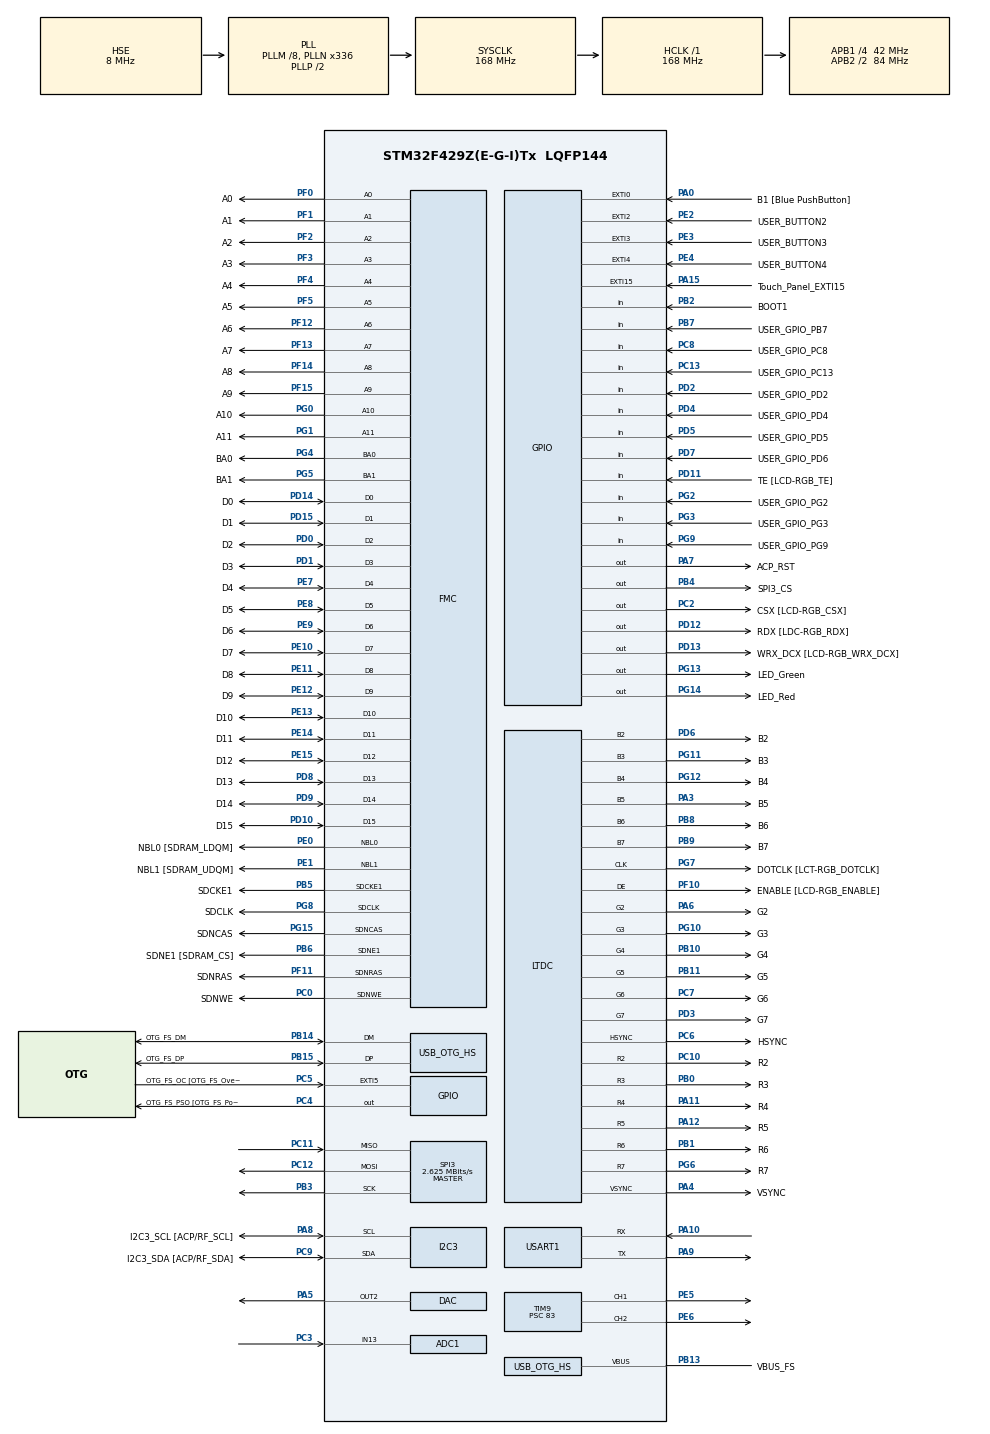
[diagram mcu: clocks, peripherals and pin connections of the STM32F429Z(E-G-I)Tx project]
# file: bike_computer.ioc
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ADC1.Channel-12\#ChannelRegularConversion=ADC_CHANNEL_13
ADC1.ClockPrescaler=ADC_CLOCK_SYNC_PCLK_DIV4
ADC1.ContinuousConvMode=ENABLE
ADC1.DMAContinuousRequests=ENABLE
ADC1.DataAlign=ADC_DATAALIGN_RIGHT
ADC1.DiscontinuousConvMode=DISABLE
ADC1.EOCSelection=ADC_EOC_SINGLE_CONV
ADC1.EnableAnalogWatchDog=false
ADC1.ExternalTrigConv=ADC_SOFTWARE_START
ADC1.ExternalTrigConvEdge=ADC_EXTERNALTRIGCONVEDGE_NONE
ADC1.InjNumberOfConversion=0
ADC1.NbrOfConversion=1
ADC1.NbrOfConversionFlag=1
ADC1.Rank-12\#ChannelRegularConversion=1
ADC1.Resolution=ADC_RESOLUTION_12B
ADC1.SamplingTime-12\#ChannelRegularConversion=ADC_SAMPLETIME_480CYCLES
ADC1.ScanConvMode=ENABLE
ADC1.master=1
Dma.ADC1.1.Direction=DMA_PERIPH_TO_MEMORY
Dma.ADC1.1.FIFOMode=DMA_FIFOMODE_DISABLE
Dma.ADC1.1.Instance=DMA2_Stream0
Dma.ADC1.1.MemDataAlignment=DMA_MDATAALIGN_WORD
Dma.ADC1.1.MemInc=DMA_MINC_ENABLE
Dma.ADC1.1.Mode=DMA_CIRCULAR
Dma.ADC1.1.PeriphDataAlignment=DMA_PDATAALIGN_WORD
Dma.ADC1.1.PeriphInc=DMA_PINC_DISABLE
Dma.ADC1.1.Priority=DMA_PRIORITY_LOW
Dma.Request0=USART1_RX
Dma.Request1=ADC1
Dma.USART1_RX.0.Direction=DMA_PERIPH_TO_MEMORY
Dma.USART1_RX.0.FIFOMode=DMA_FIFOMODE_DISABLE
Dma.USART1_RX.0.Instance=DMA2_Stream2
Dma.USART1_RX.0.MemDataAlignment=DMA_MDATAALIGN_BYTE
Dma.USART1_RX.0.MemInc=DMA_MINC_ENABLE
Dma.USART1_RX.0.Mode=DMA_CIRCULAR
Dma.USART1_RX.0.PeriphDataAlignment=DMA_PDATAALIGN_BYTE
Dma.USART1_RX.0.PeriphInc=DMA_PINC_DISABLE
Dma.USART1_RX.0.Priority=DMA_PRIORITY_LOW
FMC.CASLatency1=FMC_SDRAM_CAS_LATENCY_3
FMC.ExitSelfRefreshDelay1=7
FMC.LoadToActiveDelay1=2
FMC.RCDDelay1=2
FMC.RPDelay1=2
FMC.ReadPipeDelay1=FMC_SDRAM_RPIPE_DELAY_1
FMC.RowCycleDelay1=7
FMC.SDClockPeriod1=FMC_SDRAM_CLOCK_PERIOD_2
FMC.SelfRefreshTime1=4
FMC.WriteRecoveryTime1=3
FREERTOS.Tasks01=defaultTask,0,128,StartDefaultTask,Default,NULL
FREERTOS.configCHECK_FOR_STACK_OVERFLOW=1
FREERTOS.configTOTAL_HEAP_SIZE=30000
FREERTOS.configUSE_MALLOC_FAILED_HOOK=1
LTDC.ActiveH=320
LTDC.ActiveW=240
LTDC.Alpha_L0=255
LTDC.Alpha_L1=255
LTDC.BlendingFactor1_L0=LTDC_BLENDING_FACTOR1_PAxCA
LTDC.BlendingFactor1_L1=LTDC_BLENDING_FACTOR1_PAxCA
LTDC.BlendingFactor2_L0=LTDC_BLENDING_FACTOR2_PAxCA
LTDC.BlendingFactor2_L1=LTDC_BLENDING_FACTOR2_PAxCA
LTDC.HBP=20
LTDC.HFP=10
LTDC.HSync=10
LTDC.ImageHeight_L0=320
LTDC.ImageHeight_L1=320
LTDC.ImageWidth_L0=240
LTDC.ImageWidth_L1=240
LTDC.PCPolarity=LTDC_PCPOLARITY_IIPC
LTDC.PixelFormat_L0=LTDC_PIXEL_FORMAT_L8
LTDC.PixelFormat_L1=LTDC_PIXEL_FORMAT_L8
LTDC.VFP=4
LTDC.VSync=2
LTDC.WindowX1_L0=240
LTDC.WindowX1_L1=240
LTDC.WindowY1_L0=320
LTDC.WindowY1_L1=320
Mcu.Family=STM32F4
Mcu.Name=STM32F429Z(E-G-I)Tx
Mcu.Package=LQFP144
NVIC.DMA2_Stream0_IRQn=true\:5\:0\:false\:false\:true\:true\:false
NVIC.DMA2_Stream2_IRQn=true\:5\:0\:false\:false\:true\:true\:false
NVIC.EXTI15_10_IRQn=true\:5\:0\:false\:false\:true\:true\:true
NVIC.FMC_IRQn=true\:5\:0\:false\:false\:true\:true\:true
NVIC.LTDC_ER_IRQn=true\:5\:0\:false\:false\:true\:true\:true
NVIC.LTDC_IRQn=true\:5\:0\:false\:false\:true\:true\:true
NVIC.OTG_HS_EP1_IN_IRQn=true\:5\:0\:false\:false\:true\:true\:true
NVIC.OTG_HS_EP1_OUT_IRQn=true\:5\:0\:false\:false\:true\:true\:true
NVIC.OTG_HS_IRQn=true\:5\:0\:false\:false\:true\:true\:true
NVIC.PriorityGroup=NVIC_PRIORITYGROUP_4
NVIC.TIM1_UP_TIM10_IRQn=true\:0\:0\:false\:false\:true\:false\:false
NVIC.TimeBase=TIM1_UP_TIM10_IRQn
NVIC.TimeBaseIP=TIM1
NVIC.USART1_IRQn=true\:5\:0\:false\:false\:true\:true\:true
PA0/WKUP.GPIO_Label=B1 [Blue PushButton]
PA0/WKUP.GPIO_ModeDefaultEXTI=GPIO_MODE_EVT_RISING
PA0/WKUP.GPIO_PuPd=GPIO_NOPULL
PA0/WKUP.Signal=GPXTI0
PA10.Mode=Asynchronous
PA10.Signal=USART1_RX
PA11.GPIO_Label=R4
PA11.GPIO_Mode=GPIO_MODE_AF_PP
PA11.GPIO_PuPd=GPIO_NOPULL
PA11.GPIO_Speed=GPIO_SPEED_FREQ_LOW
PA11.Mode=RGB666
PA11.Signal=LTDC_R4
PA12.GPIO_Label=R5
PA12.GPIO_Mode=GPIO_MODE_AF_PP
PA12.GPIO_PuPd=GPIO_NOPULL
PA12.GPIO_Speed=GPIO_SPEED_FREQ_LOW
PA12.Mode=RGB666
PA12.Signal=LTDC_R5
PA13.GPIO_Label=SWDIO
PA13.Signal=SYS_JTMS-SWDIO
PA14.GPIO_Label=SWCLK
PA14.Signal=SYS_JTCK-SWCLK
PA15.GPIO_Label=Touch_Panel_EXTI15
PA15.Signal=GPXTI15
PA3.GPIO_Label=B5
PA3.GPIO_Mode=GPIO_MODE_AF_PP
PA3.GPIO_PuPd=GPIO_NOPULL
PA3.GPIO_Speed=GPIO_SPEED_FREQ_LOW
PA3.Mode=RGB666
PA3.Signal=LTDC_B5
PA4.GPIO_Label=VSYNC
PA4.GPIO_Mode=GPIO_MODE_AF_PP
PA4.GPIO_PuPd=GPIO_NOPULL
PA4.GPIO_Speed=GPIO_SPEED_FREQ_LOW
PA4.Mode=RGB666
PA4.Signal=LTDC_VSYNC
PA5.Signal=COMP_DAC2_group
PA6.GPIO_Label=G2
PA6.GPIO_Mode=GPIO_MODE_AF_PP
PA6.GPIO_PuPd=GPIO_NOPULL
PA6.GPIO_Speed=GPIO_SPEED_FREQ_LOW
PA6.Mode=RGB666
PA6.Signal=LTDC_G2
PA7.GPIO_Label=ACP_RST
PA7.GPIO_Mode=GPIO_MODE_OUTPUT_PP
PA7.GPIO_PuPd=GPIO_NOPULL
PA7.GPIO_Speed=GPIO_SPEED_FREQ_LOW
PA7.Signal=GPIO_Output
PA8.GPIO_Label=I2C3_SCL [ACP/RF_SCL]
PA8.GPIO_Mode=GPIO_MODE_AF_OD
PA8.GPIO_PuPd=GPIO_NOPULL
PA8.GPIO_Speed=GPIO_SPEED_FREQ_LOW
PA8.Mode=I2C
PA8.Signal=I2C3_SCL
PA9.Mode=Asynchronous
PA9.Signal=USART1_TX
PB0.GPIO_Label=R3
PB0.GPIO_Mode=GPIO_MODE_AF_PP
PB0.GPIO_PuPd=GPIO_NOPULL
PB0.GPIO_Speed=GPIO_SPEED_FREQ_LOW
PB0.Mode=RGB666
PB0.Signal=LTDC_R3
PB1.GPIO_Label=R6
PB1.GPIO_Mode=GPIO_MODE_AF_PP
PB1.GPIO_PuPd=GPIO_NOPULL
PB1.GPIO_Speed=GPIO_SPEED_FREQ_LOW
PB1.Mode=RGB666
PB1.Signal=LTDC_R6
PB10.GPIO_Label=G4
PB10.GPIO_Mode=GPIO_MODE_AF_PP
PB10.GPIO_PuPd=GPIO_NOPULL
PB10.GPIO_Speed=GPIO_SPEED_FREQ_LOW
PB10.Mode=RGB666
PB10.Signal=LTDC_G4
PB11.GPIO_Label=G5
PB11.GPIO_Mode=GPIO_MODE_AF_PP
PB11.GPIO_PuPd=GPIO_NOPULL
PB11.GPIO_Speed=GPIO_SPEED_FREQ_LOW
PB11.Mode=RGB666
PB11.Signal=LTDC_G5
PB12.GPIO_Label=OTG_FS_ID
PB12.GPIO_Mode=GPIO_MODE_AF_PP
PB12.GPIO_PuPd=GPIO_NOPULL
PB12.GPIO_Speed=GPIO_SPEED_FREQ_LOW
PB12.Signal=USB_OTG_HS_ID
PB13.GPIO_Label=VBUS_FS
PB13.GPIO_Mode=GPIO_MODE_INPUT
PB13.GPIO_PuPd=GPIO_NOPULL
PB13.Mode=Activate_VBUS_FS
PB13.Signal=USB_OTG_HS_VBUS
PB14.GPIO_Label=OTG_FS_DM
PB14.GPIO_Mode=GPIO_MODE_AF_PP
PB14.GPIO_PuPd=GPIO_NOPULL
PB14.GPIO_Speed=GPIO_SPEED_FREQ_LOW
PB14.Mode=Device_Only_FS
PB14.Signal=USB_OTG_HS_DM
PB15.GPIO_Label=OTG_FS_DP
PB15.GPIO_Mode=GPIO_MODE_AF_PP
PB15.GPIO_PuPd=GPIO_NOPULL
PB15.GPIO_Speed=GPIO_SPEED_FREQ_LOW
PB15.Mode=Device_Only_FS
PB15.Signal=USB_OTG_HS_DP
PB2/BOOT1.GPIO_Label=BOOT1
PB2/BOOT1.GPIO_Mode=GPIO_MODE_INPUT
PB2/BOOT1.GPIO_PuPd=GPIO_NOPULL
PB2/BOOT1.Signal=GPIO_Input
PB3.Mode=Full_Duplex_Master
PB3.Signal=SPI3_SCK
PB4.GPIO_Label=SPI3_CS
PB4.Signal=GPIO_Output
PB5.GPIO_Label=SDCKE1
PB5.GPIO_Mode=GPIO_MODE_AF_PP
PB5.GPIO_PuPd=GPIO_NOPULL
PB5.GPIO_Speed=GPIO_SPEED_FREQ_VERY_HIGH
PB5.Mode=SdramChipSelect2_1
PB5.Signal=FMC_SDCKE1
PB6.GPIO_Label=SDNE1 [SDRAM_CS]
PB6.GPIO_Mode=GPIO_MODE_AF_PP
PB6.GPIO_PuPd=GPIO_NOPULL
PB6.GPIO_Speed=GPIO_SPEED_FREQ_VERY_HIGH
PB6.Mode=SdramChipSelect2_1
PB6.Signal=FMC_SDNE1
PB7.GPIO_Label=USER_GPIO_PB7
PB7.Signal=GPIO_Input
PB8.GPIO_Label=B6
PB8.GPIO_Mode=GPIO_MODE_AF_PP
PB8.GPIO_PuPd=GPIO_NOPULL
PB8.GPIO_Speed=GPIO_SPEED_FREQ_LOW
PB8.Mode=RGB666
PB8.Signal=LTDC_B6
PB9.GPIO_Label=B7
PB9.GPIO_Mode=GPIO_MODE_AF_PP
PB9.GPIO_PuPd=GPIO_NOPULL
PB9.GPIO_Speed=GPIO_SPEED_FREQ_LOW
PB9.Mode=RGB666
PB9.Signal=LTDC_B7
PC0.GPIO_Label=SDNWE
PC0.GPIO_Mode=GPIO_MODE_AF_PP
PC0.GPIO_PuPd=GPIO_NOPULL
PC0.GPIO_Speed=GPIO_SPEED_FREQ_VERY_HIGH
PC0.Signal=FMC_SDNWE
PC10.GPIO_Label=R2
PC10.GPIO_Mode=GPIO_MODE_AF_PP
PC10.GPIO_PuPd=GPIO_NOPULL
PC10.GPIO_Speed=GPIO_SPEED_FREQ_LOW
PC10.Mode=RGB666
PC10.Signal=LTDC_R2
PC11.Mode=Full_Duplex_Master
PC11.Signal=SPI3_MISO
PC12.Mode=Full_Duplex_Master
PC12.Signal=SPI3_MOSI
PC13.GPIO_Label=USER_GPIO_PC13
PC13.Signal=GPIO_Input
PC14/OSC32_IN.GPIO_Label=PC14-OSC32_IN
PC14/OSC32_IN.Signal=RCC_OSC32_IN
PC15/OSC32_OUT.GPIO_Label=PC15-OSC32_OUT
PC15/OSC32_OUT.Signal=RCC_OSC32_OUT
PC2.GPIO_Label=CSX [LCD-RGB_CSX]
PC2.GPIO_Mode=GPIO_MODE_OUTPUT_PP
PC2.GPIO_PuPd=GPIO_NOPULL
PC2.GPIO_Speed=GPIO_SPEED_FREQ_LOW
PC2.Signal=GPIO_Output
PC3.Signal=ADCx_IN13
PC4.GPIO_Label=OTG_FS_PSO [OTG_FS_PowerSwitchOn]
PC4.GPIO_Mode=GPIO_MODE_OUTPUT_PP
PC4.GPIO_PuPd=GPIO_NOPULL
PC4.GPIO_Speed=GPIO_SPEED_FREQ_LOW
PC4.Signal=GPIO_Output
PC5.GPIO_Label=OTG_FS_OC [OTG_FS_OverCurrent]
PC5.GPIO_ModeDefaultEXTI=GPIO_MODE_EVT_RISING
PC5.Signal=GPXTI5
PC6.GPIO_Label=HSYNC
PC6.GPIO_Mode=GPIO_MODE_AF_PP
PC6.GPIO_PuPd=GPIO_NOPULL
PC6.GPIO_Speed=GPIO_SPEED_FREQ_LOW
PC6.Mode=RGB666
PC6.Signal=LTDC_HSYNC
PC7.GPIO_Label=G6
PC7.GPIO_Mode=GPIO_MODE_AF_PP
PC7.GPIO_PuPd=GPIO_NOPULL
PC7.GPIO_Speed=GPIO_SPEED_FREQ_LOW
PC7.Mode=RGB666
PC7.Signal=LTDC_G6
PC8.GPIO_Label=USER_GPIO_PC8
PC8.Signal=GPIO_Input
PC9.GPIO_Label=I2C3_SDA [ACP/RF_SDA]
PC9.GPIO_Mode=GPIO_MODE_AF_OD
PC9.GPIO_PuPd=GPIO_NOPULL
PC9.GPIO_Speed=GPIO_SPEED_FREQ_LOW
PC9.Mode=I2C
PC9.Signal=I2C3_SDA
PD0.GPIO_Label=D2
PD0.GPIO_Mode=GPIO_MODE_AF_PP
PD0.GPIO_PuPd=GPIO_NOPULL
PD0.GPIO_Speed=GPIO_SPEED_FREQ_VERY_HIGH
PD0.Signal=FMC_D2_DA2
PD1.GPIO_Label=D3
PD1.GPIO_Mode=GPIO_MODE_AF_PP
PD1.GPIO_PuPd=GPIO_NOPULL
PD1.GPIO_Speed=GPIO_SPEED_FREQ_VERY_HIGH
PD1.Signal=FMC_D3_DA3
PD10.GPIO_Label=D15
PD10.GPIO_Mode=GPIO_MODE_AF_PP
PD10.GPIO_PuPd=GPIO_NOPULL
PD10.GPIO_Speed=GPIO_SPEED_FREQ_VERY_HIGH
PD10.Signal=FMC_D15_DA15
PD11.GPIO_Label=TE [LCD-RGB_TE]
PD11.GPIO_Mode=GPIO_MODE_INPUT
PD11.GPIO_PuPd=GPIO_NOPULL
PD11.Signal=GPIO_Input
PD12.GPIO_Label=RDX [LDC-RGB_RDX]
PD12.GPIO_Mode=GPIO_MODE_OUTPUT_PP
PD12.GPIO_PuPd=GPIO_NOPULL
PD12.GPIO_Speed=GPIO_SPEED_FREQ_LOW
PD12.Signal=GPIO_Output
PD13.GPIO_Label=WRX_DCX [LCD-RGB_WRX_DCX]
PD13.GPIO_Mode=GPIO_MODE_OUTPUT_PP
PD13.GPIO_PuPd=GPIO_NOPULL
PD13.GPIO_Speed=GPIO_SPEED_FREQ_LOW
PD13.Signal=GPIO_Output
PD14.GPIO_Label=D0
PD14.GPIO_Mode=GPIO_MODE_AF_PP
PD14.GPIO_PuPd=GPIO_NOPULL
PD14.GPIO_Speed=GPIO_SPEED_FREQ_VERY_HIGH
PD14.Signal=FMC_D0_DA0
PD15.GPIO_Label=D1
PD15.GPIO_Mode=GPIO_MODE_AF_PP
PD15.GPIO_PuPd=GPIO_NOPULL
PD15.GPIO_Speed=GPIO_SPEED_FREQ_VERY_HIGH
PD15.Signal=FMC_D1_DA1
PD2.GPIO_Label=USER_GPIO_PD2
PD2.Signal=GPIO_Input
PD3.GPIO_Label=G7
PD3.GPIO_Mode=GPIO_MODE_AF_PP
PD3.GPIO_PuPd=GPIO_NOPULL
PD3.GPIO_Speed=GPIO_SPEED_FREQ_LOW
PD3.Mode=RGB666
PD3.Signal=LTDC_G7
PD4.GPIO_Label=USER_GPIO_PD4
PD4.Signal=GPIO_Input
PD5.GPIO_Label=USER_GPIO_PD5
PD5.Signal=GPIO_Input
PD6.GPIO_Label=B2
PD6.GPIO_Mode=GPIO_MODE_AF_PP
PD6.GPIO_PuPd=GPIO_NOPULL
PD6.GPIO_Speed=GPIO_SPEED_FREQ_LOW
PD6.Mode=RGB666
PD6.Signal=LTDC_B2
PD7.GPIO_Label=USER_GPIO_PD6
PD7.Signal=GPIO_Input
PD8.GPIO_Label=D13
PD8.GPIO_Mode=GPIO_MODE_AF_PP
PD8.GPIO_PuPd=GPIO_NOPULL
PD8.GPIO_Speed=GPIO_SPEED_FREQ_VERY_HIGH
PD8.Signal=FMC_D13_DA13
PD9.GPIO_Label=D14
PD9.GPIO_Mode=GPIO_MODE_AF_PP
PD9.GPIO_PuPd=GPIO_NOPULL
PD9.GPIO_Speed=GPIO_SPEED_FREQ_VERY_HIGH
PD9.Signal=FMC_D14_DA14
PE0.GPIO_Label=NBL0 [SDRAM_LDQM]
PE0.GPIO_Mode=GPIO_MODE_AF_PP
PE0.GPIO_PuPd=GPIO_NOPULL
PE0.GPIO_Speed=GPIO_SPEED_FREQ_VERY_HIGH
PE0.Signal=FMC_NBL0
PE1.GPIO_Label=NBL1 [SDRAM_UDQM]
PE1.GPIO_Mode=GPIO_MODE_AF_PP
PE1.GPIO_PuPd=GPIO_NOPULL
PE1.GPIO_Speed=GPIO_SPEED_FREQ_VERY_HIGH
PE1.Signal=FMC_NBL1
PE10.GPIO_Label=D7
PE10.GPIO_Mode=GPIO_MODE_AF_PP
PE10.GPIO_PuPd=GPIO_NOPULL
PE10.GPIO_Speed=GPIO_SPEED_FREQ_VERY_HIGH
PE10.Signal=FMC_D7_DA7
PE11.GPIO_Label=D8
PE11.GPIO_Mode=GPIO_MODE_AF_PP
PE11.GPIO_PuPd=GPIO_NOPULL
PE11.GPIO_Speed=GPIO_SPEED_FREQ_VERY_HIGH
PE11.Signal=FMC_D8_DA8
PE12.GPIO_Label=D9
PE12.GPIO_Mode=GPIO_MODE_AF_PP
PE12.GPIO_PuPd=GPIO_NOPULL
PE12.GPIO_Speed=GPIO_SPEED_FREQ_VERY_HIGH
PE12.Signal=FMC_D9_DA9
PE13.GPIO_Label=D10
PE13.GPIO_Mode=GPIO_MODE_AF_PP
PE13.GPIO_PuPd=GPIO_NOPULL
PE13.GPIO_Speed=GPIO_SPEED_FREQ_VERY_HIGH
PE13.Signal=FMC_D10_DA10
PE14.GPIO_Label=D11
PE14.GPIO_Mode=GPIO_MODE_AF_PP
PE14.GPIO_PuPd=GPIO_NOPULL
PE14.GPIO_Speed=GPIO_SPEED_FREQ_VERY_HIGH
PE14.Signal=FMC_D11_DA11
PE15.GPIO_Label=D12
PE15.GPIO_Mode=GPIO_MODE_AF_PP
PE15.GPIO_PuPd=GPIO_NOPULL
PE15.GPIO_Speed=GPIO_SPEED_FREQ_VERY_HIGH
PE15.Signal=FMC_D12_DA12
PE2.GPIO_Label=USER_BUTTON2
PE2.Signal=GPXTI2
PE3.GPIO_Label=USER_BUTTON3
PE3.Signal=GPXTI3
PE4.GPIO_Label=USER_BUTTON4
PE4.Signal=GPXTI4
PE5.Signal=S_TIM9_CH1
PE6.Signal=S_TIM9_CH2
PE7.GPIO_Label=D4
PE7.GPIO_Mode=GPIO_MODE_AF_PP
PE7.GPIO_PuPd=GPIO_NOPULL
PE7.GPIO_Speed=GPIO_SPEED_FREQ_VERY_HIGH
PE7.Signal=FMC_D4_DA4
PE8.GPIO_Label=D5
PE8.GPIO_Mode=GPIO_MODE_AF_PP
PE8.GPIO_PuPd=GPIO_NOPULL
PE8.GPIO_Speed=GPIO_SPEED_FREQ_VERY_HIGH
PE8.Signal=FMC_D5_DA5
PE9.GPIO_Label=D6
PE9.GPIO_Mode=GPIO_MODE_AF_PP
PE9.GPIO_PuPd=GPIO_NOPULL
PE9.GPIO_Speed=GPIO_SPEED_FREQ_VERY_HIGH
PE9.Signal=FMC_D6_DA6
PF0.GPIO_Label=A0
PF0.GPIO_Mode=GPIO_MODE_AF_PP
PF0.GPIO_PuPd=GPIO_NOPULL
PF0.GPIO_Speed=GPIO_SPEED_FREQ_VERY_HIGH
PF0.Signal=FMC_A0
PF1.GPIO_Label=A1
PF1.GPIO_Mode=GPIO_MODE_AF_PP
PF1.GPIO_PuPd=GPIO_NOPULL
PF1.GPIO_Speed=GPIO_SPEED_FREQ_VERY_HIGH
PF1.Signal=FMC_A1
PF10.GPIO_Label=ENABLE [LCD-RGB_ENABLE]
PF10.GPIO_Mode=GPIO_MODE_AF_PP
PF10.GPIO_PuPd=GPIO_NOPULL
PF10.GPIO_Speed=GPIO_SPEED_FREQ_LOW
PF10.Mode=RGB666
PF10.Signal=LTDC_DE
PF11.GPIO_Label=SDNRAS
PF11.GPIO_Mode=GPIO_MODE_AF_PP
PF11.GPIO_PuPd=GPIO_NOPULL
PF11.GPIO_Speed=GPIO_SPEED_FREQ_VERY_HIGH
PF11.Signal=FMC_SDNRAS
PF12.GPIO_Label=A6
PF12.GPIO_Mode=GPIO_MODE_AF_PP
PF12.GPIO_PuPd=GPIO_NOPULL
PF12.GPIO_Speed=GPIO_SPEED_FREQ_VERY_HIGH
PF12.Signal=FMC_A6
PF13.GPIO_Label=A7
PF13.GPIO_Mode=GPIO_MODE_AF_PP
PF13.GPIO_PuPd=GPIO_NOPULL
PF13.GPIO_Speed=GPIO_SPEED_FREQ_VERY_HIGH
PF13.Signal=FMC_A7
PF14.GPIO_Label=A8
PF14.GPIO_Mode=GPIO_MODE_AF_PP
PF14.GPIO_PuPd=GPIO_NOPULL
PF14.GPIO_Speed=GPIO_SPEED_FREQ_VERY_HIGH
PF14.Signal=FMC_A8
PF15.GPIO_Label=A9
PF15.GPIO_Mode=GPIO_MODE_AF_PP
PF15.GPIO_PuPd=GPIO_NOPULL
PF15.GPIO_Speed=GPIO_SPEED_FREQ_VERY_HIGH
PF15.Signal=FMC_A9
PF2.GPIO_Label=A2
PF2.GPIO_Mode=GPIO_MODE_AF_PP
PF2.GPIO_PuPd=GPIO_NOPULL
PF2.GPIO_Speed=GPIO_SPEED_FREQ_VERY_HIGH
PF2.Signal=FMC_A2
PF3.GPIO_Label=A3
PF3.GPIO_Mode=GPIO_MODE_AF_PP
PF3.GPIO_PuPd=GPIO_NOPULL
PF3.GPIO_Speed=GPIO_SPEED_FREQ_VERY_HIGH
PF3.Signal=FMC_A3
PF4.GPIO_Label=A4
PF4.GPIO_Mode=GPIO_MODE_AF_PP
PF4.GPIO_PuPd=GPIO_NOPULL
PF4.GPIO_Speed=GPIO_SPEED_FREQ_VERY_HIGH
PF4.Signal=FMC_A4
PF5.GPIO_Label=A5
PF5.GPIO_Mode=GPIO_MODE_AF_PP
PF5.GPIO_PuPd=GPIO_NOPULL
PF5.GPIO_Speed=GPIO_SPEED_FREQ_VERY_HIGH
PF5.Signal=FMC_A5
PG0.GPIO_Label=A10
PG0.GPIO_Mode=GPIO_MODE_AF_PP
PG0.GPIO_PuPd=GPIO_NOPULL
PG0.GPIO_Speed=GPIO_SPEED_FREQ_VERY_HIGH
PG0.Signal=FMC_A10
PG1.GPIO_Label=A11
PG1.GPIO_Mode=GPIO_MODE_AF_PP
PG1.GPIO_PuPd=GPIO_NOPULL
PG1.GPIO_Speed=GPIO_SPEED_FREQ_VERY_HIGH
PG1.Signal=FMC_A11
PG10.GPIO_Label=G3
PG10.GPIO_Mode=GPIO_MODE_AF_PP
PG10.GPIO_PuPd=GPIO_NOPULL
PG10.GPIO_Speed=GPIO_SPEED_FREQ_LOW
PG10.Mode=RGB666
PG10.Signal=LTDC_G3
PG11.GPIO_Label=B3
PG11.GPIO_Mode=GPIO_MODE_AF_PP
PG11.GPIO_PuPd=GPIO_NOPULL
PG11.GPIO_Speed=GPIO_SPEED_FREQ_LOW
PG11.Mode=RGB666
PG11.Signal=LTDC_B3
PG12.GPIO_Label=B4
PG12.GPIO_Mode=GPIO_MODE_AF_PP
PG12.GPIO_PuPd=GPIO_NOPULL
PG12.GPIO_Speed=GPIO_SPEED_FREQ_LOW
PG12.Mode=RGB666
PG12.Signal=LTDC_B4
PG13.GPIO_Label=LED_Green
PG13.GPIO_Mode=GPIO_MODE_OUTPUT_PP
PG13.GPIO_PuPd=GPIO_NOPULL
PG13.GPIO_Speed=GPIO_SPEED_FREQ_LOW
PG13.Signal=GPIO_Output
PG14.GPIO_Label=LED_Red
PG14.GPIO_Mode=GPIO_MODE_OUTPUT_PP
PG14.GPIO_PuPd=GPIO_NOPULL
PG14.GPIO_Speed=GPIO_SPEED_FREQ_LOW
PG14.Signal=GPIO_Output
PG15.GPIO_Label=SDNCAS
PG15.GPIO_Mode=GPIO_MODE_AF_PP
PG15.GPIO_PuPd=GPIO_NOPULL
PG15.GPIO_Speed=GPIO_SPEED_FREQ_VERY_HIGH
PG15.Signal=FMC_SDNCAS
PG2.GPIO_Label=USER_GPIO_PG2
PG2.Signal=GPIO_Input
PG3.GPIO_Label=USER_GPIO_PG3
PG3.Signal=GPIO_Input
PG4.GPIO_Label=BA0
PG4.GPIO_Mode=GPIO_MODE_AF_PP
PG4.GPIO_PuPd=GPIO_NOPULL
PG4.GPIO_Speed=GPIO_SPEED_FREQ_VERY_HIGH
PG4.Signal=FMC_A14_BA0
PG5.GPIO_Label=BA1
PG5.GPIO_Mode=GPIO_MODE_AF_PP
PG5.GPIO_PuPd=GPIO_NOPULL
PG5.GPIO_Speed=GPIO_SPEED_FREQ_VERY_HIGH
PG5.Signal=FMC_A15_BA1
PG6.GPIO_Label=R7
PG6.GPIO_Mode=GPIO_MODE_AF_PP
PG6.GPIO_PuPd=GPIO_NOPULL
PG6.GPIO_Speed=GPIO_SPEED_FREQ_LOW
PG6.Mode=RGB666
PG6.Signal=LTDC_R7
PG7.GPIO_Label=DOTCLK [LCT-RGB_DOTCLK]
PG7.GPIO_Mode=GPIO_MODE_AF_PP
PG7.GPIO_PuPd=GPIO_NOPULL
PG7.GPIO_Speed=GPIO_SPEED_FREQ_LOW
PG7.Mode=RGB666
PG7.Signal=LTDC_CLK
PG8.GPIO_Label=SDCLK
PG8.GPIO_Mode=GPIO_MODE_AF_PP
PG8.GPIO_PuPd=GPIO_NOPULL
PG8.GPIO_Speed=GPIO_SPEED_FREQ_VERY_HIGH
PG8.Signal=FMC_SDCLK
PG9.GPIO_Label=USER_GPIO_PG9
PG9.Signal=GPIO_Input
PH0/OSC_IN.GPIO_Label=PH0-OSC_IN
PH0/OSC_IN.Mode=HSE-External-Oscillator
PH0/OSC_IN.Signal=RCC_OSC_IN
PH1/OSC_OUT.GPIO_Label=PH1-OSC_OUT
PH1/OSC_OUT.Mode=HSE-External-Oscillator
PH1/OSC_OUT.Signal=RCC_OSC_OUT
ProjectManager.HeapSize=0x200
ProjectManager.StackSize=0x400
ProjectManager.TargetToolchain=TrueSTUDIO
RCC.48MHZClocksFreq_Value=48000000
RCC.AHBFreq_Value=168000000
RCC.APB1CLKDivider=RCC_HCLK_DIV4
RCC.APB1Freq_Value=42000000
RCC.APB1TimFreq_Value=84000000
RCC.APB2CLKDivider=RCC_HCLK_DIV2
RCC.APB2Freq_Value=84000000
RCC.APB2TimFreq_Value=168000000
RCC.CortexFreq_Value=168000000
RCC.HCLKFreq_Value=168000000
RCC.HSE_VALUE=8000000
RCC.HSI_VALUE=16000000
RCC.LSE_VALUE=32768
RCC.PLLM=8
RCC.PLLN=336
RCC.PLLQ=7
RCC.PLLSAIDivR=RCC_PLLSAIDIVR_8
RCC.PLLSAIN=192
RCC.PLLSAIR=4
RCC.SYSCLKFreq_VALUE=168000000
RCC.SYSCLKSource=RCC_SYSCLKSOURCE_PLLCLK
RCC.VCOOutputFreq_Value=336000000
SH.ADCx_IN13.0=ADC1_IN13,IN13
SH.COMP_DAC2_group.0=DAC_OUT2,DAC_OUT2
SH.FMC_A0.0=FMC_A0,12b-sda1
SH.FMC_A1.0=FMC_A1,12b-sda1
SH.FMC_A10.0=FMC_A10,12b-sda1
SH.FMC_A11.0=FMC_A11,12b-sda1
SH.FMC_A14_BA0.0=FMC_BA0,FourSdramBanks1
SH.FMC_A15_BA1.0=FMC_BA1,FourSdramBanks1
SH.FMC_A2.0=FMC_A2,12b-sda1
SH.FMC_A3.0=FMC_A3,12b-sda1
SH.FMC_A4.0=FMC_A4,12b-sda1
SH.FMC_A5.0=FMC_A5,12b-sda1
SH.FMC_A6.0=FMC_A6,12b-sda1
SH.FMC_A7.0=FMC_A7,12b-sda1
SH.FMC_A8.0=FMC_A8,12b-sda1
SH.FMC_A9.0=FMC_A9,12b-sda1
SH.FMC_D0_DA0.0=FMC_D0,sd-16b-d1
SH.FMC_D10_DA10.0=FMC_D10,sd-16b-d1
SH.FMC_D11_DA11.0=FMC_D11,sd-16b-d1
SH.FMC_D12_DA12.0=FMC_D12,sd-16b-d1
SH.FMC_D13_DA13.0=FMC_D13,sd-16b-d1
SH.FMC_D14_DA14.0=FMC_D14,sd-16b-d1
SH.FMC_D15_DA15.0=FMC_D15,sd-16b-d1
SH.FMC_D1_DA1.0=FMC_D1,sd-16b-d1
SH.FMC_D2_DA2.0=FMC_D2,sd-16b-d1
SH.FMC_D3_DA3.0=FMC_D3,sd-16b-d1
SH.FMC_D4_DA4.0=FMC_D4,sd-16b-d1
SH.FMC_D5_DA5.0=FMC_D5,sd-16b-d1
SH.FMC_D6_DA6.0=FMC_D6,sd-16b-d1
SH.FMC_D7_DA7.0=FMC_D7,sd-16b-d1
SH.FMC_D8_DA8.0=FMC_D8,sd-16b-d1
SH.FMC_D9_DA9.0=FMC_D9,sd-16b-d1
SH.FMC_NBL0.0=FMC_NBL0,Sd2ByteEnable1
SH.FMC_NBL1.0=FMC_NBL1,Sd2ByteEnable1
SH.FMC_SDCLK.0=FMC_SDCLK,12b-sda1
SH.FMC_SDNCAS.0=FMC_SDNCAS,12b-sda1
SH.FMC_SDNRAS.0=FMC_SDNRAS,12b-sda1
SH.FMC_SDNWE.0=FMC_SDNWE,12b-sda1
SH.S_TIM9_CH1.0=TIM9_CH1,PWM Generation1 CH1
SH.S_TIM9_CH2.0=TIM9_CH2,PWM Generation2 CH2
SPI3.BaudRatePrescaler=SPI_BAUDRATEPRESCALER_16
SPI3.CalculateBaudRate=2.625 MBits/s
SPI3.Direction=SPI_DIRECTION_2LINES
SPI3.Mode=SPI_MODE_MASTER
SPI3.VirtualType=VM_MASTER
TIM9.Channel-PWM\ Generation1\ CH1=TIM_CHANNEL_1
TIM9.Channel-PWM\ Generation2\ CH2=TIM_CHANNEL_2
TIM9.Period=4999
TIM9.Prescaler=83
USART1.VirtualMode=VM_ASYNC
USB_DEVICE.CLASS_NAME_HS=CDC
USB_DEVICE.VirtualMode-CDC_HS=Cdc
USB_DEVICE.VirtualModeHS=Cdc_HS
USB_OTG_HS.VirtualMode-Device_Only_FS=Device_Only_FS
USB_OTG_HS.vbus_sensing_enable-Device_Only_FS=ENABLE
VP_FREERTOS_VS_ENABLE.Mode=Enabled
VP_SYS_VS_tim1.Mode=TIM1
VP_USB_DEVICE_VS_USB_DEVICE_CDC_HS.Mode=CDC_HS
board=STM32F429I-DISCO

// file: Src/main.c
/**
  ******************************************************************************
  * File Name          : main.c
  * Description        : Main program body
  ******************************************************************************
  * This notice applies to any and all portions of this file
  * that are not between comment pairs USER CODE BEGIN and
  * USER CODE END. Other portions of this file, whether
  * inserted by the user or by software development tools
  * are owned by their respective copyright owners.
  *
  * Copyright (c) 2017 STMicroelectronics International N.V.
  * All rights reserved.
  *
  * Redistribution and use in source and binary forms, with or without
  * modification, are permitted, provided that the following conditions are met:
  *
  * 1. Redistribution of source code must retain the above copyright notice,
  *    this list of conditions and the following disclaimer.
  * 2. Redistributions in binary form must reproduce the above copyright notice,
  *    this list of conditions and the following disclaimer in the documentation
  *    and/or other materials provided with the distribution.
  * 3. Neither the name of STMicroelectronics nor the names of other
  *    contributors to this software may be used to endorse or promote products
  *    derived from this software without specific written permission.
  * 4. This software, including modifications and/or derivative works of this
  *    software, must execute solely and exclusively on microcontroller or
  *    microprocessor devices manufactured by or for STMicroelectronics.
  * 5. Redistribution and use of this software other than as permitted under
  *    this license is void and will automatically terminate your rights under
  *    this license.
  *
  * THIS SOFTWARE IS PROVIDED BY STMICROELECTRONICS AND CONTRIBUTORS "AS IS"
  * AND ANY EXPRESS, IMPLIED OR STATUTORY WARRANTIES, INCLUDING, BUT NOT
  * LIMITED TO, THE IMPLIED WARRANTIES OF MERCHANTABILITY, FITNESS FOR A
  * PARTICULAR PURPOSE AND NON-INFRINGEMENT OF THIRD PARTY INTELLECTUAL PROPERTY
  * RIGHTS ARE DISCLAIMED TO THE FULLEST EXTENT PERMITTED BY LAW. IN NO EVENT
  * SHALL STMICROELECTRONICS OR CONTRIBUTORS BE LIABLE FOR ANY DIRECT, INDIRECT,
  * INCIDENTAL, SPECIAL, EXEMPLARY, OR CONSEQUENTIAL DAMAGES (INCLUDING, BUT NOT
  * LIMITED TO, PROCUREMENT OF SUBSTITUTE GOODS OR SERVICES; LOSS OF USE, DATA,
  * OR PROFITS; OR BUSINESS INTERRUPTION) HOWEVER CAUSED AND ON ANY THEORY OF
  * LIABILITY, WHETHER IN CONTRACT, STRICT LIABILITY, OR TORT (INCLUDING
  * NEGLIGENCE OR OTHERWISE) ARISING IN ANY WAY OUT OF THE USE OF THIS SOFTWARE,
  * EVEN IF ADVISED OF THE POSSIBILITY OF SUCH DAMAGE.
  *
  ******************************************************************************
  */
#include "main.h"
#include "stm32f4xx_hal.h"
#include "cmsis_os.h"
#include "adc.h"
#include "dac.h"
#include "dma.h"
#include "i2c.h"
#include "ltdc.h"
#include "spi.h"
#include "tim.h"
#include "usart.h"
#include "usb_device.h"
#include "gpio.h"
#include "fmc.h"

/* USER CODE BEGIN Includes */
#include "stm32f4xx_hal_ltdc.h"

//LCD and SDRAM includes
//includes for lcd
#include "stm32f429i_discovery.h"
#include "ili9341.h"
#include "Graphics.h"
#include "Memory.h"
#include "TouchPanel.h"
#include "ButtonWidget.h"

/* USER CODE END Includes */

/* USER CODE BEGIN PV */
/* Private variables ---------------------------------------------------------*/

/* USER CODE END PV */

void SystemClock_Config(void);
void MX_FREERTOS_Init(void);

/* USER CODE BEGIN PFP */
/* Private function prototypes -----------------------------------------------*/

/* USER CODE END PFP */

/* USER CODE BEGIN 0 */
//extern QueueHandle_t PanelQueue;
/* USER CODE END 0 */

int main(void)
{

  /* MCU Configuration----------------------------------------------------------*/

  /* Reset of all peripherals, Initializes the Flash interface and the Systick. */
  HAL_Init();

  /* Configure the system clock */
  SystemClock_Config();

  /* Initialize all configured peripherals */
  MX_GPIO_Init();
  MX_DMA_Init();
  MX_FMC_Init();
  MX_LTDC_Init();
  MX_USART1_UART_Init();
  MX_DAC_Init();
  MX_SPI3_Init();
  MX_I2C3_Init();
  MX_TIM9_Init();
  MX_ADC1_Init();

  /* USER CODE BEGIN 2 */

	//init SDRAM
	SDRAM_Initialization_sequence(REFRESH_COUNT);

	//init pages with color
	LCD_Clear(0, BLACK);
	LCD_Clear(1, BLACK);

	//init the LCD
	ili9341_Init();

	//configure the pallet and look up tables
	HAL_LTDC_ConfigCLUT(&hltdc, colorPalletRGB332 , 256, 0);
	HAL_LTDC_ConfigCLUT(&hltdc, colorPalletRGB332 , 256, 1);
	HAL_LTDC_EnableCLUT(&hltdc, 0);
	HAL_LTDC_EnableCLUT(&hltdc, 1);

	//set the starting address of frame buffer layers
	//to SDRAM addresses
	HAL_LTDC_SetAddress(&hltdc, (uint32_t)SDRAM_LCD_LAYER_0, 0);
	HAL_LTDC_SetAddress(&hltdc, (uint32_t)SDRAM_LCD_LAYER_1, 1);

	//init the touch panel
	TouchPanel_init();

  /* USER CODE END 2 */

  /* Call init function for freertos objects (in freertos.c) */
  MX_FREERTOS_Init();

  /* Start scheduler */
  osKernelStart();

  /* We should never get here as control is now taken by the scheduler */

  /* Infinite loop */
	while (1)
	{

	}

}

/** System Clock Configuration
*/
void SystemClock_Config(void)
{

  RCC_OscInitTypeDef RCC_OscInitStruct;
  RCC_ClkInitTypeDef RCC_ClkInitStruct;
  RCC_PeriphCLKInitTypeDef PeriphClkInitStruct;

    /**Configure the main internal regulator output voltage
    */
  __HAL_RCC_PWR_CLK_ENABLE();

  __HAL_PWR_VOLTAGESCALING_CONFIG(PWR_REGULATOR_VOLTAGE_SCALE1);

    /**Initializes the CPU, AHB and APB busses clocks
    */
  RCC_OscInitStruct.OscillatorType = RCC_OSCILLATORTYPE_HSE;
  RCC_OscInitStruct.HSEState = RCC_HSE_ON;
  RCC_OscInitStruct.PLL.PLLState = RCC_PLL_ON;
  RCC_OscInitStruct.PLL.PLLSource = RCC_PLLSOURCE_HSE;
  RCC_OscInitStruct.PLL.PLLM = 8;
  RCC_OscInitStruct.PLL.PLLN = 336;
  RCC_OscInitStruct.PLL.PLLP = RCC_PLLP_DIV2;
  RCC_OscInitStruct.PLL.PLLQ = 7;
  if (HAL_RCC_OscConfig(&RCC_OscInitStruct) != HAL_OK)
  {
    _Error_Handler(__FILE__, __LINE__);
  }

    /**Initializes the CPU, AHB and APB busses clocks
    */
  RCC_ClkInitStruct.ClockType = RCC_CLOCKTYPE_HCLK|RCC_CLOCKTYPE_SYSCLK
                              |RCC_CLOCKTYPE_PCLK1|RCC_CLOCKTYPE_PCLK2;
  RCC_ClkInitStruct.SYSCLKSource = RCC_SYSCLKSOURCE_PLLCLK;
  RCC_ClkInitStruct.AHBCLKDivider = RCC_SYSCLK_DIV1;
  RCC_ClkInitStruct.APB1CLKDivider = RCC_HCLK_DIV4;
  RCC_ClkInitStruct.APB2CLKDivider = RCC_HCLK_DIV2;

  if (HAL_RCC_ClockConfig(&RCC_ClkInitStruct, FLASH_LATENCY_5) != HAL_OK)
  {
    _Error_Handler(__FILE__, __LINE__);
  }

  PeriphClkInitStruct.PeriphClockSelection = RCC_PERIPHCLK_LTDC;
  PeriphClkInitStruct.PLLSAI.PLLSAIN = 192;
  PeriphClkInitStruct.PLLSAI.PLLSAIR = 4;
  PeriphClkInitStruct.PLLSAIDivR = RCC_PLLSAIDIVR_8;
  if (HAL_RCCEx_PeriphCLKConfig(&PeriphClkInitStruct) != HAL_OK)
  {
    _Error_Handler(__FILE__, __LINE__);
  }

    /**Configure the Systick interrupt time
    */
  HAL_SYSTICK_Config(HAL_RCC_GetHCLKFreq()/1000);

    /**Configure the Systick
    */
  HAL_SYSTICK_CLKSourceConfig(SYSTICK_CLKSOURCE_HCLK);

  /* SysTick_IRQn interrupt configuration */
  HAL_NVIC_SetPriority(SysTick_IRQn, 15, 0);
}

void HAL_TIM_PeriodElapsedCallback(TIM_HandleTypeDef *htim)
{
  if (htim->Instance == TIM1) {
    HAL_IncTick();
  }
}

void _Error_Handler(char * file, int line)
{
  while(1)
  {
  }
}

/************************ (C) COPYRIGHT STMicroelectronics *****END OF FILE****/

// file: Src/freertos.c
/**
  ******************************************************************************
  * File Name          : freertos.c
  * Description        : Code for freertos applications
  ******************************************************************************
  * This notice applies to any and all portions of this file
  * that are not between comment pairs USER CODE BEGIN and
  * USER CODE END. Other portions of this file, whether
  * inserted by the user or by software development tools
  * are owned by their respective copyright owners.
  *
  * Copyright (c) 2017 STMicroelectronics International N.V.
  * All rights reserved.
  *
  * Redistribution and use in source and binary forms, with or without
  * modification, are permitted, provided that the following conditions are met:
  *
  * 1. Redistribution of source code must retain the above copyright notice,
  *    this list of conditions and the following disclaimer.
  * 2. Redistributions in binary form must reproduce the above copyright notice,
  *    this list of conditions and the following disclaimer in the documentation
  *    and/or other materials provided with the distribution.
  * 3. Neither the name of STMicroelectronics nor the names of other
  *    contributors to this software may be used to endorse or promote products
  *    derived from this software without specific written permission.
  * 4. This software, including modifications and/or derivative works of this
  *    software, must execute solely and exclusively on microcontroller or
  *    microprocessor devices manufactured by or for STMicroelectronics.
  * 5. Redistribution and use of this software other than as permitted under
  *    this license is void and will automatically terminate your rights under
  *    this license.
  *
  * THIS SOFTWARE IS PROVIDED BY STMICROELECTRONICS AND CONTRIBUTORS "AS IS"
  * AND ANY EXPRESS, IMPLIED OR STATUTORY WARRANTIES, INCLUDING, BUT NOT
  * LIMITED TO, THE IMPLIED WARRANTIES OF MERCHANTABILITY, FITNESS FOR A
  * PARTICULAR PURPOSE AND NON-INFRINGEMENT OF THIRD PARTY INTELLECTUAL PROPERTY
  * RIGHTS ARE DISCLAIMED TO THE FULLEST EXTENT PERMITTED BY LAW. IN NO EVENT
  * SHALL STMICROELECTRONICS OR CONTRIBUTORS BE LIABLE FOR ANY DIRECT, INDIRECT,
  * INCIDENTAL, SPECIAL, EXEMPLARY, OR CONSEQUENTIAL DAMAGES (INCLUDING, BUT NOT
  * LIMITED TO, PROCUREMENT OF SUBSTITUTE GOODS OR SERVICES; LOSS OF USE, DATA,
  * OR PROFITS; OR BUSINESS INTERRUPTION) HOWEVER CAUSED AND ON ANY THEORY OF
  * LIABILITY, WHETHER IN CONTRACT, STRICT LIABILITY, OR TORT (INCLUDING
  * NEGLIGENCE OR OTHERWISE) ARISING IN ANY WAY OUT OF THE USE OF THIS SOFTWARE,
  * EVEN IF ADVISED OF THE POSSIBILITY OF SUCH DAMAGE.
  *
  ******************************************************************************
  */

#include "FreeRTOS.h"
#include "task.h"
#include "cmsis_os.h"

/* USER CODE BEGIN Includes */
#include "queue.h"

#include "gpio.h"		//toggle LED_Green, LED_Red

#include "Memory.h"		//SDRAM layer definitions
#include "ltdc.h"		//layer control

#include "TouchPanel.h"
#include "ButtonWidget.h"

/* USER CODE END Includes */

osThreadId defaultTaskHandle;

/* USER CODE BEGIN Variables */

osThreadId panelTaskHandle;

QueueHandle_t PanelQueue;

/* USER CODE END Variables */

void StartDefaultTask(void const * argument);

extern void MX_USB_DEVICE_Init(void);
void MX_FREERTOS_Init(void); /* (MISRA C 2004 rule 8.1) */

/* USER CODE BEGIN FunctionPrototypes */

void StartPanelTask(void const * argument);

/* USER CODE END FunctionPrototypes */

/* Hook prototypes */
void vApplicationStackOverflowHook(xTaskHandle xTask, signed char *pcTaskName);
void vApplicationMallocFailedHook(void);

/* USER CODE BEGIN 4 */
__weak void vApplicationStackOverflowHook(xTaskHandle xTask, signed char *pcTaskName)
{
   /* Run time stack overflow checking is performed if
   configCHECK_FOR_STACK_OVERFLOW is defined to 1 or 2. This hook function is
   called if a stack overflow is detected. */
	while(1)
	{

	}
}
/* USER CODE END 4 */

/* USER CODE BEGIN 5 */
__weak void vApplicationMallocFailedHook(void)
{
   /* vApplicationMallocFailedHook() will only be called if
   configUSE_MALLOC_FAILED_HOOK is set to 1 in FreeRTOSConfig.h. It is a hook
   function that will get called if a call to pvPortMalloc() fails.
   pvPortMalloc() is called internally by the kernel whenever a task, queue,
   timer or semaphore is created. It is also called by various parts of the
   demo application. If heap_1.c or heap_2.c are used, then the size of the
   heap available to pvPortMalloc() is defined by configTOTAL_HEAP_SIZE in
   FreeRTOSConfig.h, and the xPortGetFreeHeapSize() API function can be used
   to query the size of free heap space that remains (although it does not
   provide information on how the remaining heap might be fragmented). */

	while(1)
	{

	}
}
/* USER CODE END 5 */

/* Init FreeRTOS */

void MX_FREERTOS_Init(void) {

  /* Create the thread(s) */
  /* definition and creation of defaultTask */
  osThreadDef(defaultTask, StartDefaultTask, osPriorityNormal, 0, 128);
  defaultTaskHandle = osThreadCreate(osThread(defaultTask), NULL);

  /* USER CODE BEGIN RTOS_THREADS */
  /* add threads, ... */

  osThreadDef(panelTask, StartPanelTask, osPriorityNormal, 0, 128);
  panelTaskHandle = osThreadCreate(osThread(panelTask), NULL);

  //queue of ButtonWidgets
  PanelQueue = xQueueCreate(6, sizeof(ButtonWidget_t));

  /* USER CODE END RTOS_THREADS */

}

/* StartDefaultTask function */
void StartDefaultTask(void const * argument)
{
	/* init code for USB_DEVICE */
	MX_USB_DEVICE_Init();

	/* USER CODE BEGIN StartDefaultTask */
	uint8_t buffer[16];
	int n;
	TouchPanelData tpData;			//for reading panel location

	LCD_SetTextBackColor(RED);
	LCD_SetTextLineColor(BLUE);
	LCD_Clear(0, RED);
	HAL_LTDC_SetAddress(&hltdc, (uint32_t)SDRAM_LCD_LAYER_0, 0);
	HAL_LTDC_SetAddress(&hltdc, (uint32_t)SDRAM_LCD_LAYER_1, 1);

	/* Infinite loop */
	for(;;)
	{
		HAL_GPIO_TogglePin(GPIOG, LED_Red_Pin);

		tpData = TouchPanel_getPosition();			//read the current touch position

		//write the position
		n = sprintf((char*)buffer, "Xpos: %d   ", tpData.xPos);
		LCD_DrawStringLength(0,1, buffer, (uint8_t)n);
		n = sprintf((char*)buffer, "Ypos: %d   ", tpData.yPos);
		LCD_DrawStringLength(0,2, buffer, (uint8_t)n);
		n = sprintf((char*)buffer, "Xraw: %d   ", tpData.xRawPos);
		LCD_DrawStringLength(0,3, buffer, (uint8_t)n);
		n = sprintf((char*)buffer, "Yraw: %d   ", tpData.yRawPos);
		LCD_DrawStringLength(0,4, buffer, (uint8_t)n);

	//	ButtonWidget_DrawButtons(10);

		LCD_DrawBox(0, 0, 120, 80, 80, GREEN);
		LCD_DrawBox(0, 0, 200, 80, 80, BLUE);

		osDelay(500);

	}

  /* USER CODE END StartDefaultTask */
}

/* USER CODE BEGIN Application */

////////////////////////////////////////////
//touch panel task
//receives a message from a queue to
//evaluate which button was pressed
//
void StartPanelTask(void const * argument)
{
	ButtonWidget_t button;
	ButtonState_t state;

	for(;;)
	{
		if (pdPASS == xQueueReceive(PanelQueue, &button, portMAX_DELAY))
		{
			//read the current state
			state = button.btnState;

			//toggle the state
			if (state == BUTTON_STATE_OFF)
				ButtonWidget_SetButtonState(button, BUTTON_STATE_ON);
			else if (state == BUTTON_STATE_ON)
				ButtonWidget_SetButtonState(button, BUTTON_STATE_OFF);

			//run the handler function

			//function pointer:
			//void (*buttonHandler)(void);	//function to run

			//fuunction declaration
			//btnFunction1
			//calling the handler:
			//(*button.buttonHandler)();

			(*button.buttonHandler)();
		}
	}

	vTaskDelete(NULL);
}

/* USER CODE END Application */

/************************ (C) COPYRIGHT STMicroelectronics *****END OF FILE****/
